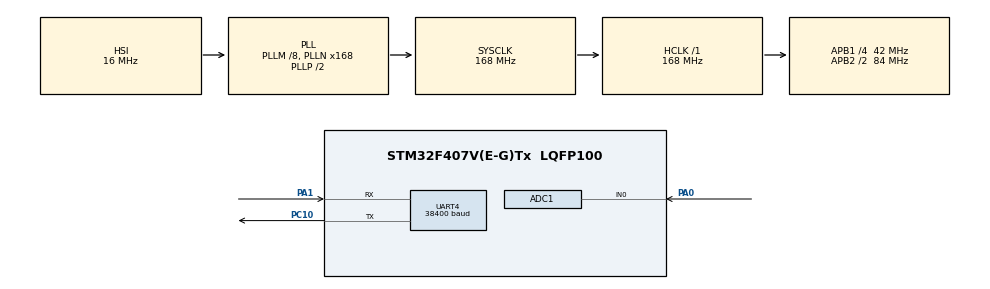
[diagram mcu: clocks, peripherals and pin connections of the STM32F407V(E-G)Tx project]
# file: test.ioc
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ADC1.Channel-0\#ChannelRegularConversion=ADC_CHANNEL_0
ADC1.NbrOfConversionFlag=1
ADC1.Rank-0\#ChannelRegularConversion=1
ADC1.SamplingTime-0\#ChannelRegularConversion=ADC_SAMPLETIME_3CYCLES
ADC1.master=1
Dma.Request0=UART4_RX
Dma.UART4_RX.0.Direction=DMA_PERIPH_TO_MEMORY
Dma.UART4_RX.0.FIFOMode=DMA_FIFOMODE_DISABLE
Dma.UART4_RX.0.Instance=DMA1_Stream2
Dma.UART4_RX.0.MemDataAlignment=DMA_MDATAALIGN_BYTE
Dma.UART4_RX.0.MemInc=DMA_MINC_ENABLE
Dma.UART4_RX.0.Mode=DMA_CIRCULAR
Dma.UART4_RX.0.PeriphDataAlignment=DMA_PDATAALIGN_BYTE
Dma.UART4_RX.0.PeriphInc=DMA_PINC_DISABLE
Dma.UART4_RX.0.Priority=DMA_PRIORITY_LOW
Mcu.Family=STM32F4
Mcu.Name=STM32F407V(E-G)Tx
Mcu.Package=LQFP100
NVIC.DMA1_Stream2_IRQn=true\:0\:0\:false\:false\:true\:false\:true\:true
NVIC.PriorityGroup=NVIC_PRIORITYGROUP_0
NVIC.UART4_IRQn=true\:0\:0\:false\:false\:true\:true\:true\:true
PA0-WKUP.Signal=ADCx_IN0
PA1.Mode=Asynchronous
PA1.Signal=UART4_RX
PC10.Mode=Asynchronous
PC10.Signal=UART4_TX
PC14-OSC32_IN.Mode=LSE-External-Oscillator
PC14-OSC32_IN.Signal=RCC_OSC32_IN
PC15-OSC32_OUT.Mode=LSE-External-Oscillator
PC15-OSC32_OUT.Signal=RCC_OSC32_OUT
PH0-OSC_IN.Mode=HSE-External-Oscillator
PH0-OSC_IN.Signal=RCC_OSC_IN
PH1-OSC_OUT.Mode=HSE-External-Oscillator
PH1-OSC_OUT.Signal=RCC_OSC_OUT
ProjectManager.HeapSize=0x200
ProjectManager.StackSize=0x400
ProjectManager.TargetToolchain=STM32CubeIDE
RCC.48MHZClocksFreq_Value=48000000
RCC.AHBFreq_Value=168000000
RCC.APB1CLKDivider=RCC_HCLK_DIV4
RCC.APB1Freq_Value=42000000
RCC.APB1TimFreq_Value=84000000
RCC.APB2CLKDivider=RCC_HCLK_DIV2
RCC.APB2Freq_Value=84000000
RCC.APB2TimFreq_Value=168000000
RCC.CortexFreq_Value=168000000
RCC.HCLKFreq_Value=168000000
RCC.HSE_VALUE=8000000
RCC.HSI_VALUE=16000000
RCC.PLLM=8
RCC.PLLN=168
RCC.PLLQ=7
RCC.SYSCLKFreq_VALUE=168000000
RCC.SYSCLKSource=RCC_SYSCLKSOURCE_PLLCLK
RCC.VCOOutputFreq_Value=336000000
SH.ADCx_IN0.0=ADC1_IN0,IN0
UART4.BaudRate=38400
UART4.Mode=MODE_TX_RX
UART4.StopBits=UART_STOPBITS_2
UART4.VirtualMode=Asynchronous
board=STM32F407G-DISC1

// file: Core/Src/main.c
/* USER CODE BEGIN Header */
/**
  ******************************************************************************
  * @file           : main.c
  * @brief          : Main program body
  ******************************************************************************
  * @attention
  *
  * Copyright (c) 2023 STMicroelectronics.
  * All rights reserved.
  *
  * This software is licensed under terms that can be found in the LICENSE file
  * in the root directory of this software component.
  * If no LICENSE file comes with this software, it is provided AS-IS.
  *
  ******************************************************************************
  */
/* USER CODE END Header */
#include "main.h"

ADC_HandleTypeDef hadc1;

UART_HandleTypeDef huart4;
DMA_HandleTypeDef hdma_uart4_rx;

void SystemClock_Config(void);
static void MX_GPIO_Init(void);
static void MX_DMA_Init(void);
static void MX_UART4_Init(void);
static void MX_ADC1_Init(void);

int main(void)
{
  /* USER CODE BEGIN 1 */
	uint32_t potValue = 0;
  /* USER CODE END 1 */

  /* MCU Configuration--------------------------------------------------------*/

  /* Reset of all peripherals, Initializes the Flash interface and the Systick. */
  HAL_Init();

  /* Configure the system clock */
  SystemClock_Config();

  /* Initialize all configured peripherals */
  MX_GPIO_Init();
  MX_DMA_Init();
  MX_UART4_Init();
  MX_ADC1_Init();

  /* Infinite loop */
  while (1)
  {
	    HAL_ADC_Start(&hadc1);
	    if (HAL_ADC_PollForConversion(&hadc1, 100) == HAL_OK)
	    {
	      potValue = HAL_ADC_GetValue(&hadc1);
	    }
	    HAL_ADC_Stop(&hadc1);

	    // Map Potentiometer Value to Speed
	    uint8_t motorSpeed = (uint8_t)(potValue / 16);  // Map the potentiometer value to motor speed range
	    												// 12-bit ADC resolution
	    												// 3.3V reference Voltage
	    // Set motor speeds
	    uint8_t setSpeed1Cmd[] = {0x00, 0x31, motorSpeed};         // SET SPEED 1 command
	    uint8_t setSpeed2Cmd[] = {0x00, 0x32, motorSpeed};         // SET SPEED 2 command

	    HAL_UART_Transmit(&huart4, setSpeed1Cmd, sizeof(setSpeed1Cmd), HAL_MAX_DELAY);
	    HAL_UART_Transmit(&huart4, setSpeed2Cmd, sizeof(setSpeed2Cmd), HAL_MAX_DELAY);

  }
}

void SystemClock_Config(void)
{
  RCC_OscInitTypeDef RCC_OscInitStruct = {0};
  RCC_ClkInitTypeDef RCC_ClkInitStruct = {0};

  /** Configure the main internal regulator output voltage
  */
  __HAL_RCC_PWR_CLK_ENABLE();
  __HAL_PWR_VOLTAGESCALING_CONFIG(PWR_REGULATOR_VOLTAGE_SCALE1);

  /** Initializes the RCC Oscillators according to the specified parameters
  * in the RCC_OscInitTypeDef structure.
  */
  RCC_OscInitStruct.OscillatorType = RCC_OSCILLATORTYPE_HSI;
  RCC_OscInitStruct.HSIState = RCC_HSI_ON;
  RCC_OscInitStruct.HSICalibrationValue = RCC_HSICALIBRATION_DEFAULT;
  RCC_OscInitStruct.PLL.PLLState = RCC_PLL_ON;
  RCC_OscInitStruct.PLL.PLLSource = RCC_PLLSOURCE_HSI;
  RCC_OscInitStruct.PLL.PLLM = 8;
  RCC_OscInitStruct.PLL.PLLN = 168;
  RCC_OscInitStruct.PLL.PLLP = RCC_PLLP_DIV2;
  RCC_OscInitStruct.PLL.PLLQ = 7;
  if (HAL_RCC_OscConfig(&RCC_OscInitStruct) != HAL_OK)
  {
    Error_Handler();
  }

  /** Initializes the CPU, AHB and APB buses clocks
  */
  RCC_ClkInitStruct.ClockType = RCC_CLOCKTYPE_HCLK|RCC_CLOCKTYPE_SYSCLK
                              |RCC_CLOCKTYPE_PCLK1|RCC_CLOCKTYPE_PCLK2;
  RCC_ClkInitStruct.SYSCLKSource = RCC_SYSCLKSOURCE_PLLCLK;
  RCC_ClkInitStruct.AHBCLKDivider = RCC_SYSCLK_DIV1;
  RCC_ClkInitStruct.APB1CLKDivider = RCC_HCLK_DIV4;
  RCC_ClkInitStruct.APB2CLKDivider = RCC_HCLK_DIV2;

  if (HAL_RCC_ClockConfig(&RCC_ClkInitStruct, FLASH_LATENCY_5) != HAL_OK)
  {
    Error_Handler();
  }
}

static void MX_ADC1_Init(void)
{

  ADC_ChannelConfTypeDef sConfig = {0};

  /** Configure the global features of the ADC (Clock, Resolution, Data Alignment and number of conversion)
  */
  hadc1.Instance = ADC1;
  hadc1.Init.ClockPrescaler = ADC_CLOCK_SYNC_PCLK_DIV4;
  hadc1.Init.Resolution = ADC_RESOLUTION_12B;
  hadc1.Init.ScanConvMode = DISABLE;
  hadc1.Init.ContinuousConvMode = DISABLE;
  hadc1.Init.DiscontinuousConvMode = DISABLE;
  hadc1.Init.ExternalTrigConvEdge = ADC_EXTERNALTRIGCONVEDGE_NONE;
  hadc1.Init.ExternalTrigConv = ADC_SOFTWARE_START;
  hadc1.Init.DataAlign = ADC_DATAALIGN_RIGHT;
  hadc1.Init.NbrOfConversion = 1;
  hadc1.Init.DMAContinuousRequests = DISABLE;
  hadc1.Init.EOCSelection = ADC_EOC_SINGLE_CONV;
  if (HAL_ADC_Init(&hadc1) != HAL_OK)
  {
    Error_Handler();
  }

  /** Configure for the selected ADC regular channel its corresponding rank in the sequencer and its sample time.
  */
  sConfig.Channel = ADC_CHANNEL_0;
  sConfig.Rank = 1;
  sConfig.SamplingTime = ADC_SAMPLETIME_3CYCLES;
  if (HAL_ADC_ConfigChannel(&hadc1, &sConfig) != HAL_OK)
  {
    Error_Handler();
  }

}

static void MX_UART4_Init(void)
{

  huart4.Instance = UART4;
  huart4.Init.BaudRate = 38400;
  huart4.Init.WordLength = UART_WORDLENGTH_8B;
  huart4.Init.StopBits = UART_STOPBITS_2;
  huart4.Init.Parity = UART_PARITY_NONE;
  huart4.Init.Mode = UART_MODE_TX_RX;
  huart4.Init.HwFlowCtl = UART_HWCONTROL_NONE;
  huart4.Init.OverSampling = UART_OVERSAMPLING_16;
  if (HAL_UART_Init(&huart4) != HAL_OK)
  {
    Error_Handler();
  }

}

static void MX_DMA_Init(void)
{

  /* DMA controller clock enable */
  __HAL_RCC_DMA1_CLK_ENABLE();

  /* DMA interrupt init */
  /* DMA1_Stream2_IRQn interrupt configuration */
  HAL_NVIC_SetPriority(DMA1_Stream2_IRQn, 0, 0);
  HAL_NVIC_EnableIRQ(DMA1_Stream2_IRQn);

}

static void MX_GPIO_Init(void)
{

  /* GPIO Ports Clock Enable */
  __HAL_RCC_GPIOC_CLK_ENABLE();
  __HAL_RCC_GPIOH_CLK_ENABLE();
  __HAL_RCC_GPIOA_CLK_ENABLE();

}

void Error_Handler(void)
{
  __disable_irq();
  while (1)
  {
  }
}
